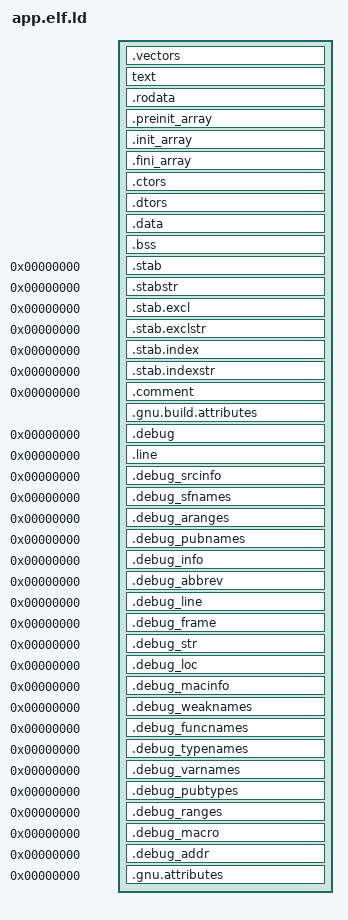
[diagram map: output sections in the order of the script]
__stack = ORIGIN(dram_seg) + LENGTH(dram_seg);
__MIN_STACK_SIZE = 0x1000;

ENTRY(_start)
SECTIONS
{
  . = SEGMENT_START("iram_seg", 0);
  .vectors    :
  {
    _vector_table = ABSOLUTE(.);
    . = 0x0;
    KEEP(*(.WindowVectors.text));
    . = 0x180;
    KEEP(*(.Level2InterruptVector.text));
    . = 0x1c0;
    KEEP(*(.Level3InterruptVector.text));
    . = 0x200;
    KEEP(*(.Level4InterruptVector.text));
    . = 0x240;
    KEEP(*(.Level5InterruptVector.text));
    . = 0x280;
    KEEP(*(.DebugExceptionVector.text));
    . = 0x2c0;
    KEEP(*(.NMIExceptionVector.text));
    . = 0x300;
    KEEP(*(.KernelExceptionVector.text));
    . = 0x340;
    KEEP(*(.UserExceptionVector.text));
    . = 0x3C0;
    KEEP(*(.DoubleExceptionVector.text));
    . = 0x400;
    KEEP(*(.ResetVector.text));
    *(.*Vector.literal)
    . = ALIGN (16);
  } > iram_seg

  text    :
  {
    KEEP (*(.init.literal))
    KEEP (*(SORT_NONE(.init)))
    *(.literal .text .stub .literal.* .text.* .gnu.linkonce.literal.* .gnu.linkonce.t.*.literal .gnu.linkonce.t.*)
    /* .gnu.warning sections are handled specially by elf32.em.  */
    *(.gnu.warning)
    KEEP (*(.fini.literal))
    KEEP (*(SORT_NONE(.fini)))
  } > iram_seg

  PROVIDE (__etext = .);
  PROVIDE (_etext = .);
  PROVIDE (etext = .);

  /* Adjust the address for the data segment.  We want to adjust up to
     the same address within the page on the next page up.  */
  . = ALIGN (CONSTANT (MAXPAGESIZE)) - ((CONSTANT (MAXPAGESIZE) - .) & (CONSTANT (MAXPAGESIZE) - 1)); . = DATA_SEGMENT_ALIGN (CONSTANT (MAXPAGESIZE), CONSTANT (COMMONPAGESIZE));

  .rodata    :
  {
    *(.rodata .rodata.* .gnu.linkonce.r.*)
    *(.rodata1)
    *(.sdata2 .sdata2.* .gnu.linkonce.s2.*)
    *(.sbss2 .sbss2.* .gnu.linkonce.sb2.*)
  }

  .preinit_array    :
  {
    PROVIDE_HIDDEN (__preinit_array_start = .);
    KEEP (*(.preinit_array))
    PROVIDE_HIDDEN (__preinit_array_end = .);
  }
  .init_array    :
  {
    PROVIDE_HIDDEN (__init_array_start = .);
    KEEP (*(SORT_BY_INIT_PRIORITY(.init_array.*) SORT_BY_INIT_PRIORITY(.ctors.*)))
    KEEP (*(.init_array EXCLUDE_FILE (*crtbegin.o *crtbegin?.o *crtend.o *crtend?.o ) .ctors))
    PROVIDE_HIDDEN (__init_array_end = .);
  }
  .fini_array    :
  {
    PROVIDE_HIDDEN (__fini_array_start = .);
    KEEP (*(SORT_BY_INIT_PRIORITY(.fini_array.*) SORT_BY_INIT_PRIORITY(.dtors.*)))
    KEEP (*(.fini_array EXCLUDE_FILE (*crtbegin.o *crtbegin?.o *crtend.o *crtend?.o ) .dtors))
    PROVIDE_HIDDEN (__fini_array_end = .);
  }
  .ctors          :
  {
    /* gcc uses crtbegin.o to find the start of
       the constructors, so we make sure it is
       first.  Because this is a wildcard, it
       doesn't matter if the user does not
       actually link against crtbegin.o; the
       linker won't look for a file to match a
       wildcard.  The wildcard also means that it
       doesn't matter which directory crtbegin.o
       is in.  */
    KEEP (*crtbegin.o(.ctors))
    KEEP (*crtbegin?.o(.ctors))
    /* We don't want to include the .ctor section from
       the crtend.o file until after the sorted ctors.
       The .ctor section from the crtend file contains the
       end of ctors marker and it must be last */
    KEEP (*(EXCLUDE_FILE (*crtend.o *crtend?.o ) .ctors))
    KEEP (*(SORT(.ctors.*)))
    KEEP (*(.ctors))
  }
  .dtors          :
  {
    KEEP (*crtbegin.o(.dtors))
    KEEP (*crtbegin?.o(.dtors))
    KEEP (*(EXCLUDE_FILE (*crtend.o *crtend?.o ) .dtors))
    KEEP (*(SORT(.dtors.*)))
    KEEP (*(.dtors))
  }

  _data_start = .;
  .data          :
  {
    *(.data .data.* .gnu.linkonce.d.*)
    SORT(CONSTRUCTORS)
    *(.data1)
  }
  _edata = .; PROVIDE (edata = .);
  . = .;
  __bss_start = .;
  .bss            :
  {
    *(.dynsbss)
    *(.sbss .sbss.* .gnu.linkonce.sb.*)
    *(.scommon)
    *(.dynbss)
    *(.bss .bss.* .gnu.linkonce.b.*)
    *(COMMON)
    /* Align here to ensure that the .bss section occupies space up to
      _end.  Align after .bss to ensure correct alignment even if the
      .bss section disappears because there are no input sections.
      FIXME: Why do we need it? When there is no .bss section, we do not
      pad the .data section.  */
    . = ALIGN(. != 0 ? 32 / 8 : 1);
  }
  . = ALIGN(32 / 8);
  . = ALIGN(32 / 8);
  _end = .; PROVIDE (end = .);
  . = DATA_SEGMENT_END (.);

  /* Check if data + heap + stack exceeds RAM limit */
  ASSERT(. <= __stack - __MIN_STACK_SIZE, "region DRAM overflowed by .data and .bss sections")

  /* Stabs debugging sections.  */
  .stab          0 : { *(.stab) }
  .stabstr       0 : { *(.stabstr) }
  .stab.excl     0 : { *(.stab.excl) }
  .stab.exclstr  0 : { *(.stab.exclstr) }
  .stab.index    0 : { *(.stab.index) }
  .stab.indexstr 0 : { *(.stab.indexstr) }
  .comment       0 : { *(.comment) }
  .gnu.build.attributes : { *(.gnu.build.attributes .gnu.build.attributes.*) }
  /* DWARF debug sections.
     Symbols in the DWARF debugging sections are relative to the beginning
     of the section so we begin them at 0.  */
  /* DWARF 1 */
  .debug          0 : { *(.debug) }
  .line           0 : { *(.line) }
  /* GNU DWARF 1 extensions */
  .debug_srcinfo  0 : { *(.debug_srcinfo) }
  .debug_sfnames  0 : { *(.debug_sfnames) }
  /* DWARF 1.1 and DWARF 2 */
  .debug_aranges  0 : { *(.debug_aranges) }
  .debug_pubnames 0 : { *(.debug_pubnames) }
  /* DWARF 2 */
  .debug_info     0 : { *(.debug_info .gnu.linkonce.wi.*) }
  .debug_abbrev   0 : { *(.debug_abbrev) }
  .debug_line     0 : { *(.debug_line .debug_line.* .debug_line_end) }
  .debug_frame    0 : { *(.debug_frame) }
  .debug_str      0 : { *(.debug_str) }
  .debug_loc      0 : { *(.debug_loc) }
  .debug_macinfo  0 : { *(.debug_macinfo) }
  /* SGI/MIPS DWARF 2 extensions */
  .debug_weaknames 0 : { *(.debug_weaknames) }
  .debug_funcnames 0 : { *(.debug_funcnames) }
  .debug_typenames 0 : { *(.debug_typenames) }
  .debug_varnames  0 : { *(.debug_varnames) }
  /* DWARF 3 */
  .debug_pubtypes 0 : { *(.debug_pubtypes) }
  .debug_ranges   0 : { *(.debug_ranges) }
  /* DWARF Extension.  */
  .debug_macro    0 : { *(.debug_macro) }
  .debug_addr     0 : { *(.debug_addr) }
  .gnu.attributes 0 : { KEEP (*(.gnu.attributes)) }
  /DISCARD/ : { *(.note.GNU-stack) *(.gnu_debuglink) *(.gnu.lto_*) }
}

